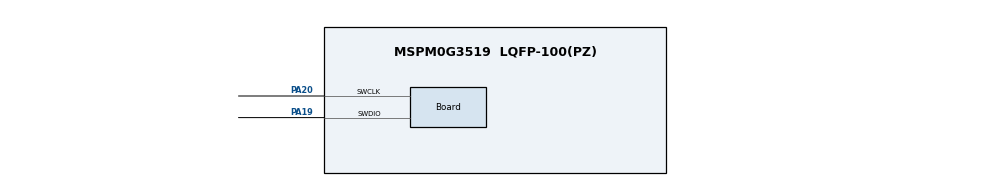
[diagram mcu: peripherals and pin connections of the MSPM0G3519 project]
//@cliArgs --device "MSPM0G351X" --package "LQFP-100(PZ)" --part "Default"
//@v2CliArgs --device "MSPM0G3519" --package "LQFP-100(PZ)"
// @cliArgs --board /ti/boards/LP_MSPM0G3519 --rtos nortos

/**
 * Import the modules used in this configuration.
 */
const ADC12  = scripting.addModule("/ti/driverlib/ADC12", {}, false);
const ADC121 = ADC12.addInstance();
const Board  = scripting.addModule("/ti/driverlib/Board");
const SYSCTL = scripting.addModule("/ti/driverlib/SYSCTL");

/**
 * Write custom configuration values to the imported modules.
 */
ADC121.$name                          = "ADC12_0";
ADC121.repeatMode                     = true;
ADC121.sampleTime0                    = "62.5 ns";
ADC121.powerDownMode                  = "DL_ADC12_POWER_DOWN_MODE_MANUAL";
ADC121.enableFIFO                     = true;
ADC121.configureDMA                   = true;
ADC121.sampCnt                        = 6;
ADC121.enabledDMATriggers             = ["DL_ADC12_DMA_MEM10_RESULT_LOADED"];
ADC121.enabledInterrupts              = ["DL_ADC12_INTERRUPT_DMA_DONE"];
ADC121.adcMem0chansel                 = "DL_ADC12_INPUT_CHAN_12";
ADC121.peripheral.$assign             = "ADC0";
ADC121.peripheral.adcPin12.$assign    = "PA14";
ADC121.DMA_CHANNEL.$name              = "DMA_CH0";
ADC121.DMA_CHANNEL.addressMode        = "f2b";
ADC121.DMA_CHANNEL.peripheral.$assign = "DMA_CH0";
ADC121.adcPin12Config.$name           = "ti_driverlib_gpio_GPIOPinGeneric0";

Board.peripheral.$assign          = "DEBUGSS";
Board.peripheral.swclkPin.$assign = "PA20";
Board.peripheral.swdioPin.$assign = "PA19";

SYSCTL.forceDefaultClkConfig = true;
SYSCTL.clockTreeEn           = true;

const ProjectConfig              = scripting.addModule("/ti/project_config/ProjectConfig", {}, false);
ProjectConfig.migrationCondition = true;
